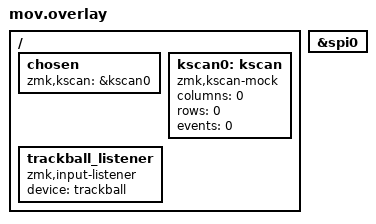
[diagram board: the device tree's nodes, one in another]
#include <dt-bindings/zmk/matrix_transform.h>
#include "pmw3610.dtsi"

/ {
    chosen {
		zmk,kscan = &kscan0;
	};

    kscan0: kscan {
        compatible = "zmk,kscan-mock";
        columns = <0>;
        rows = <0>;

        events = <0>;
    };
}

&spi0 {
    status = "okay";
};

/ {
  trackball_listener {
    compatible = "zmk,input-listener";
    status = "okay";
    device = <&trackball>;
  };
}; 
